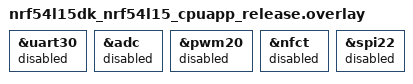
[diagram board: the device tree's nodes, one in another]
/*
 * Copyright (c) 2025 Nordic Semiconductor ASA
 *
 * SPDX-License-Identifier: LicenseRef-Nordic-5-Clause
 */

#include "nrf54l15dk_nrf54l15_cpuapp.overlay"

&uart30 {
	status = "disabled";
};

&adc {
	status = "disabled";
};

&pwm20 {
	status = "disabled";
};

&nfct {
	status = "disabled";
};

&spi22 {
	status = "disabled";
};
